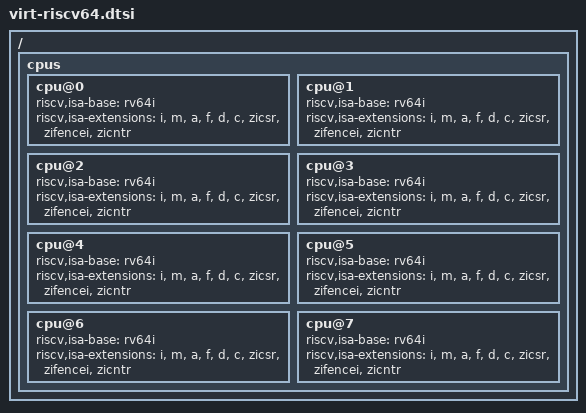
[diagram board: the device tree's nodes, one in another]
/*
 * Copyright (c) 2024 Antmicro <www.antmicro.com>
 *
 * SPDX-License-Identifier: Apache-2.0
 */

/dts-v1/;

#include <qemu/virt-riscv.dtsi>

/ {
	cpus {
		cpu@0 {
			riscv,isa-base = "rv64i";
			riscv,isa-extensions = "i", "m", "a", "f", "d", "c", "zicsr", "zifencei",
					       "zicntr";
		};

		cpu@1 {
			riscv,isa-base = "rv64i";
			riscv,isa-extensions = "i", "m", "a", "f", "d", "c", "zicsr", "zifencei",
					       "zicntr";
		};

		cpu@2 {
			riscv,isa-base = "rv64i";
			riscv,isa-extensions = "i", "m", "a", "f", "d", "c", "zicsr", "zifencei",
					       "zicntr";
		};

		cpu@3 {
			riscv,isa-base = "rv64i";
			riscv,isa-extensions = "i", "m", "a", "f", "d", "c", "zicsr", "zifencei",
					       "zicntr";
		};

		cpu@4 {
			riscv,isa-base = "rv64i";
			riscv,isa-extensions = "i", "m", "a", "f", "d", "c", "zicsr", "zifencei",
					       "zicntr";
		};

		cpu@5 {
			riscv,isa-base = "rv64i";
			riscv,isa-extensions = "i", "m", "a", "f", "d", "c", "zicsr", "zifencei",
					       "zicntr";
		};

		cpu@6 {
			riscv,isa-base = "rv64i";
			riscv,isa-extensions = "i", "m", "a", "f", "d", "c", "zicsr", "zifencei",
					       "zicntr";
		};

		cpu@7 {
			riscv,isa-base = "rv64i";
			riscv,isa-extensions = "i", "m", "a", "f", "d", "c", "zicsr", "zifencei",
					       "zicntr";
		};
	};
};
